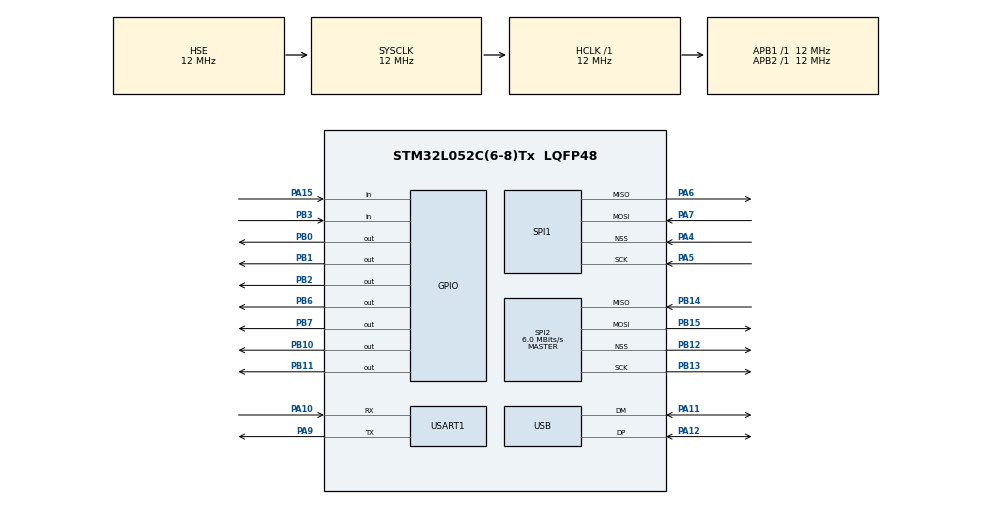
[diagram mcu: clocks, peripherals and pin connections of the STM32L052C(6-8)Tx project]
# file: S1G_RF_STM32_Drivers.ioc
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Mcu.Family=STM32L0
Mcu.Name=STM32L052C(6-8)Tx
Mcu.Package=LQFP48
NVIC.USB_IRQn=true\:0\:0\:false\:false\:true
PA10.Mode=Asynchronous
PA10.Signal=USART1_RX
PA11.Mode=Device
PA11.Signal=USB_DM
PA12.Mode=Device
PA12.Signal=USB_DP
PA13.Mode=Serial_Wire
PA13.Signal=SYS_SWDIO
PA14.Mode=Serial_Wire
PA14.Signal=SYS_SWCLK
PA15.Signal=GPIO_Input
PA4.Mode=NSS_Signal_Hard_Input
PA4.Signal=SPI1_NSS
PA5.Mode=Full_Duplex_Slave
PA5.Signal=SPI1_SCK
PA6.Mode=Full_Duplex_Slave
PA6.Signal=SPI1_MISO
PA7.Mode=Full_Duplex_Slave
PA7.Signal=SPI1_MOSI
PA9.Mode=Asynchronous
PA9.Signal=USART1_TX
PB0.Signal=GPIO_Output
PB1.Signal=GPIO_Output
PB10.Signal=GPIO_Output
PB11.Signal=GPIO_Output
PB12.Mode=NSS_Signal_Hard_Output
PB12.Signal=SPI2_NSS
PB13.Mode=Full_Duplex_Master
PB13.Signal=SPI2_SCK
PB14.Mode=Full_Duplex_Master
PB14.Signal=SPI2_MISO
PB15.Mode=Full_Duplex_Master
PB15.Signal=SPI2_MOSI
PB2.Signal=GPIO_Output
PB3.Signal=GPIO_Input
PB6.Signal=GPIO_Output
PB7.Signal=GPIO_Output
PH0-OSC_IN.Mode=HSE-External-Oscillator
PH0-OSC_IN.Signal=RCC_OSC_IN
PH1-OSC_OUT.Mode=HSE-External-Oscillator
PH1-OSC_OUT.Signal=RCC_OSC_OUT
ProjectManager.HeapSize=0x200
ProjectManager.StackSize=0x400
ProjectManager.TargetToolchain=SW4STM32
RCC.AHBFreq_Value=12000000
RCC.APB1Freq_Value=12000000
RCC.APB1TimFreq_Value=12000000
RCC.APB2Freq_Value=12000000
RCC.APB2TimFreq_Value=12000000
RCC.EnbaleCSS=true
RCC.HCLKFreq_Value=12000000
RCC.HSE_VALUE=12000000
RCC.HSI16_VALUE=16000000
RCC.HSI48_VALUE=48000000
RCC.HSI_VALUE=16000000
RCC.LSE_VALUE=32768
RCC.MSI_VALUE=2097000
RCC.PLLMUL=RCC_PLLMUL_8
RCC.SYSCLKFreq_VALUE=12000000
RCC.SYSCLKSource=RCC_SYSCLKSOURCE_HSE
RCC.Usart1ClockSelection=RCC_USART1CLKSOURCE_SYSCLK
RCC.VCOOutputFreq_Value=96000000
SPI1.VirtualNSS=VM_NSSHARD
SPI1.VirtualType=VM_SLAVE
SPI2.BaudRatePrescaler=SPI_BAUDRATEPRESCALER_2
SPI2.CalculateBaudRate=6.0 MBits/s
SPI2.Mode=SPI_MODE_MASTER
SPI2.VirtualNSS=VM_NSSHARD
USB_DEVICE.CLASS_NAME_FS=CDC
USB_DEVICE.USBD_HandleTypeDef=hUsbDeviceFS
USB_DEVICE.VirtualMode=Cdc
USB_DEVICE.VirtualModeFS=Cdc_FS
VP_USB_DEVICE_VS_USB_DEVICE_CDC_FS.Mode=CDC_FS
board=S1G_RF_STM32_Drivers

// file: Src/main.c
/**
  ******************************************************************************
  * File Name          : main.c
  * Description        : Main program body
  ******************************************************************************
  *
  * Copyright (c) 2016 STMicroelectronics International N.V.
  * All rights reserved.
  *
  * Redistribution and use in source and binary forms, with or without
  * modification, are permitted, provided that the following conditions are met:
  *
  * 1. Redistribution of source code must retain the above copyright notice,
  *    this list of conditions and the following disclaimer.
  * 2. Redistributions in binary form must reproduce the above copyright notice,
  *    this list of conditions and the following disclaimer in the documentation
  *    and/or other materials provided with the distribution.
  * 3. Neither the name of STMicroelectronics nor the names of other
  *    contributors to this software may be used to endorse or promote products
  *    derived from this software without specific written permission.
  * 4. This software, including modifications and/or derivative works of this
  *    software, must execute solely and exclusively on microcontroller or
  *    microprocessor devices manufactured by or for STMicroelectronics.
  * 5. Redistribution and use of this software other than as permitted under
  *    this license is void and will automatically terminate your rights under
  *    this license.
  *
  * THIS SOFTWARE IS PROVIDED BY STMICROELECTRONICS AND CONTRIBUTORS "AS IS"
  * AND ANY EXPRESS, IMPLIED OR STATUTORY WARRANTIES, INCLUDING, BUT NOT
  * LIMITED TO, THE IMPLIED WARRANTIES OF MERCHANTABILITY, FITNESS FOR A
  * PARTICULAR PURPOSE AND NON-INFRINGEMENT OF THIRD PARTY INTELLECTUAL PROPERTY
  * RIGHTS ARE DISCLAIMED TO THE FULLEST EXTENT PERMITTED BY LAW. IN NO EVENT
  * SHALL STMICROELECTRONICS OR CONTRIBUTORS BE LIABLE FOR ANY DIRECT, INDIRECT,
  * INCIDENTAL, SPECIAL, EXEMPLARY, OR CONSEQUENTIAL DAMAGES (INCLUDING, BUT NOT
  * LIMITED TO, PROCUREMENT OF SUBSTITUTE GOODS OR SERVICES; LOSS OF USE, DATA,
  * OR PROFITS; OR BUSINESS INTERRUPTION) HOWEVER CAUSED AND ON ANY THEORY OF
  * LIABILITY, WHETHER IN CONTRACT, STRICT LIABILITY, OR TORT (INCLUDING
  * NEGLIGENCE OR OTHERWISE) ARISING IN ANY WAY OUT OF THE USE OF THIS SOFTWARE,
  * EVEN IF ADVISED OF THE POSSIBILITY OF SUCH DAMAGE.
  *
  ******************************************************************************
  */
#include "main.h"
#include "stm32l0xx_hal.h"
#include "spi.h"
#include "usart.h"
#include "usb_device.h"
#include "gpio.h"

/* USER CODE BEGIN Includes */
#include "ADF7023.h"

/* USER CODE END Includes */

/* USER CODE BEGIN PV */
/* Private variables ---------------------------------------------------------*/

/* USER CODE END PV */

void SystemClock_Config(void);
void Error_Handler(void);

/* USER CODE BEGIN PFP */
/* Private function prototypes -----------------------------------------------*/

/* USER CODE END PFP */

int main(void)
{

  /* MCU Configuration----------------------------------------------------------*/

  /* Reset of all peripherals, Initializes the Flash interface and the Systick. */
  HAL_Init();

  /* Configure the system clock */
  SystemClock_Config();

  /* Initialize all configured peripherals */
  MX_GPIO_Init();
  MX_SPI1_Init();
  MX_SPI2_Init();
  MX_USART1_UART_Init();
  MX_USB_DEVICE_Init();

  /* Infinite loop */
  while (1)
  {

  }

}

/** System Clock Configuration
*/
void SystemClock_Config(void)
{

  RCC_OscInitTypeDef RCC_OscInitStruct;
  RCC_ClkInitTypeDef RCC_ClkInitStruct;
  RCC_PeriphCLKInitTypeDef PeriphClkInit;

    /**Configure the main internal regulator output voltage
    */
  __HAL_PWR_VOLTAGESCALING_CONFIG(PWR_REGULATOR_VOLTAGE_SCALE1);

    /**Initializes the CPU, AHB and APB busses clocks
    */
  RCC_OscInitStruct.OscillatorType = RCC_OSCILLATORTYPE_HSE;
  RCC_OscInitStruct.HSEState = RCC_HSE_ON;
  RCC_OscInitStruct.PLL.PLLState = RCC_PLL_ON;
  RCC_OscInitStruct.PLL.PLLSource = RCC_PLLSOURCE_HSE;
  RCC_OscInitStruct.PLL.PLLMUL = RCC_PLLMUL_8;
  RCC_OscInitStruct.PLL.PLLDIV = RCC_PLLDIV_2;
  if (HAL_RCC_OscConfig(&RCC_OscInitStruct) != HAL_OK)
  {
    Error_Handler();
  }

    /**Initializes the CPU, AHB and APB busses clocks
    */
  RCC_ClkInitStruct.ClockType = RCC_CLOCKTYPE_HCLK|RCC_CLOCKTYPE_SYSCLK
                              |RCC_CLOCKTYPE_PCLK1|RCC_CLOCKTYPE_PCLK2;
  RCC_ClkInitStruct.SYSCLKSource = RCC_SYSCLKSOURCE_HSE;
  RCC_ClkInitStruct.AHBCLKDivider = RCC_SYSCLK_DIV1;
  RCC_ClkInitStruct.APB1CLKDivider = RCC_HCLK_DIV1;
  RCC_ClkInitStruct.APB2CLKDivider = RCC_HCLK_DIV1;

  if (HAL_RCC_ClockConfig(&RCC_ClkInitStruct, FLASH_LATENCY_0) != HAL_OK)
  {
    Error_Handler();
  }

  PeriphClkInit.PeriphClockSelection = RCC_PERIPHCLK_USART1|RCC_PERIPHCLK_USB;
  PeriphClkInit.Usart1ClockSelection = RCC_USART1CLKSOURCE_SYSCLK;
  PeriphClkInit.UsbClockSelection = RCC_USBCLKSOURCE_PLL;
  if (HAL_RCCEx_PeriphCLKConfig(&PeriphClkInit) != HAL_OK)
  {
    Error_Handler();
  }

    /**Enables the Clock Security System
    */
  HAL_RCC_EnableCSS();

    /**Configure the Systick interrupt time
    */
  HAL_SYSTICK_Config(HAL_RCC_GetHCLKFreq()/1000);

    /**Configure the Systick
    */
  HAL_SYSTICK_CLKSourceConfig(SYSTICK_CLKSOURCE_HCLK);

  /* SysTick_IRQn interrupt configuration */
  HAL_NVIC_SetPriority(SysTick_IRQn, 0, 0);
}

void Error_Handler(void)
{
  while(1)
  {
  }
}

/************************ (C) COPYRIGHT STMicroelectronics *****END OF FILE****/
